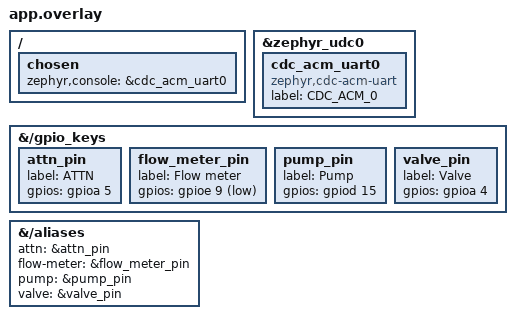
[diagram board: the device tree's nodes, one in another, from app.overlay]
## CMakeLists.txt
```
# Copyright 2023 Blues Inc.  All rights reserved.
# Use of this source code is governed by licenses granted by the
# copyright holder including that found in the LICENSE file.

# SPDX-License-Identifier: MIT

# Set CMake policy behavior
cmake_minimum_required(VERSION 3.20.0)

# Load Zephyr Package
find_package(Zephyr REQUIRED HINTS $ENV{ZEPHYR_BASE})

# Basic Project Configuration
project(nf9
    VERSION 1.0.0
    LANGUAGES C ASM
)
set(CMAKE_C_STANDARD 11)
set(CMAKE_C_STANDARD_REQUIRED ON)
set(CMAKE_C_EXTENSIONS ON)  # required for inline asm

# Create variables to alias path names
set(NOTE_C ${CMAKE_CURRENT_LIST_DIR}/note-c)
set(SRC ${CMAKE_CURRENT_LIST_DIR}/src)

# Set global compile settings
zephyr_get_compile_options_for_lang_as_string(C zephyr_options)
message(STATUS ${zephyr_options})
message(STATUS) # Insert blank line for readability
zephyr_compile_options(
    -ggdb
    -Og
    -Wall
    # -Wextra
    -Wno-unused-parameter
    # -Wpedantic
)
zephyr_get_compile_options_for_lang_as_string(C zephyr_options)
message(STATUS ${zephyr_options})
message(STATUS) # Insert blank line for readability

# Let Zephyr build additional 3rd party libs (e.g. `note-c`) with `app`
target_sources(app
    PRIVATE ${NOTE_C}/n_atof.c
    PRIVATE ${NOTE_C}/n_b64.c
    PRIVATE ${NOTE_C}/n_cjson.c
    PRIVATE ${NOTE_C}/n_cjson_helpers.c
    PRIVATE ${NOTE_C}/n_const.c
    PRIVATE ${NOTE_C}/n_ftoa.c
    PRIVATE ${NOTE_C}/n_helpers.c
    PRIVATE ${NOTE_C}/n_hooks.c
    PRIVATE ${NOTE_C}/n_i2c.c
    PRIVATE ${NOTE_C}/n_md5.c
    PRIVATE ${NOTE_C}/n_printf.c
    PRIVATE ${NOTE_C}/n_request.c
    PRIVATE ${NOTE_C}/n_serial.c
    PRIVATE ${NOTE_C}/n_str.c
    PRIVATE ${NOTE_C}/n_ua.c
    PRIVATE ${SRC}/main.c
    PRIVATE ${SRC}/notecard.c
)

target_include_directories(app
    PRIVATE ${NOTE_C}
)

target_compile_definitions(app
    PRIVATE -DUSE_VALVE=1
)

# WARNING: These options are overriden by `zephyr_compile_options()`
target_compile_options(app
    PRIVATE -ggdb
    PRIVATE -Og
    PRIVATE -Wall
    PRIVATE -Wextra
    # PRIVATE -Wpedantic
    PRIVATE -Wimplicit-fallthrough=2
    PRIVATE -Wunused-parameter
)
```

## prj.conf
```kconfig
CONFIG_GPIO=y
CONFIG_USB_DEVICE_STACK=y
CONFIG_USB_DEVICE_PRODUCT="Notecard Valve Monitor"
CONFIG_USB_DEVICE_VID=4440

CONFIG_SERIAL=y
CONFIG_CONSOLE=y
CONFIG_UART_CONSOLE=y
CONFIG_UART_LINE_CTRL=y

CONFIG_I2C=y

CONFIG_NEWLIB_LIBC=y

# Debugging Configuration
# CONFIG_OPENOCD_SUPPORT=y
CONFIG_PRINTK=y
```

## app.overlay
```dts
/*
 * Copyright (c) 2021 Nordic Semiconductor ASA
 *
 * SPDX-License-Identifier: Apache-2.0
 */

/ {
	chosen {
		zephyr,console = &cdc_acm_uart0;
	};
};

&zephyr_udc0 {
	cdc_acm_uart0: cdc_acm_uart0 {
		compatible = "zephyr,cdc-acm-uart";
		label = "CDC_ACM_0";
	};
};

&{/gpio_keys} {
	attn_pin: attn_pin {
		label = "ATTN";
		gpios = <&gpioa 5 GPIO_ACTIVE_HIGH>;
	};

	flow_meter_pin: flow_meter_pin {
		label = "Flow meter";
		gpios = <&gpioe 9 GPIO_ACTIVE_LOW>;
	};

	pump_pin: pump_pin {
		label = "Pump";
		gpios = <&gpiod 15 GPIO_ACTIVE_HIGH>;
	};

	valve_pin: valve_pin {
		label = "Valve";
		gpios = <&gpioa 4 GPIO_ACTIVE_HIGH>;
	};
};

&{/aliases} {
	attn = &attn_pin;
	flow-meter = &flow_meter_pin;
	pump = &pump_pin;
	valve = &valve_pin;
};
```

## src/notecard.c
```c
#include "notecard.h"

#include <zephyr/drivers/i2c.h>
#include <zephyr/drivers/uart.h>
#include <zephyr/kernel.h>

static const size_t REQUEST_HEADER_SIZE = 2;

const struct device *i2c_dev = NULL;
bool i2c1_initialized = false;

uint32_t platform_millis(void)
{
    return k_uptime_get_32();
}

void platform_delay(uint32_t ms)
{
    k_msleep(ms);
}

const char *noteI2cReceive(uint16_t device_address_, uint8_t *buffer_, uint16_t size_, uint32_t *available_)
{
    // Let the Notecard know that we are getting ready to read some data
    uint8_t size_buf[2];
    size_buf[0] = 0;
    size_buf[1] = (uint8_t)size_;
    uint8_t write_result = i2c_write(i2c_dev, size_buf, sizeof(size_buf), device_address_);

    if (write_result != 0)
    {
        return "i2c: Unable to initate read from the Notecard\n";
    }

    // Read from the Notecard and copy the response bytes into the response buffer
    const int request_length = size_ + REQUEST_HEADER_SIZE;
    uint8_t read_buf[256];
    uint8_t read_result = i2c_read(i2c_dev, read_buf, request_length, device_address_);

    if (read_result != 0)
    {
        return "i2c: Unable to receive data from the Notecard.\n";
    }
    else
    {
        *available_ = (uint32_t)read_buf[0];
        uint8_t bytes_to_read = read_buf[1];
        for (size_t i = 0; i < bytes_to_read; i++)
        {
            buffer_[i] = read_buf[i + 2];
        }

        return NULL;
    }
}

bool noteI2cReset(uint16_t device_address_)
{
    (void)device_address_;

    if (i2c1_initialized)
        return true;

    if (!i2c_dev)
    {
        i2c_dev = DEVICE_DT_GET(DT_NODELABEL(i2c1));
    }

    if (!device_is_ready(i2c_dev))
    {
        printk("i2c: Device is not ready.\n");

        return false;
    }

    printk("i2c: Device is ready.\n");

    i2c1_initialized = true;
    return true;
}

const char *noteI2cTransmit(uint16_t device_address_, uint8_t *buffer_, uint16_t size_)
{
    // Create a buffer that contains the number of bytes and the data to write to the Notecard
    uint8_t write_buf[size_ + 1];
    write_buf[0] = (uint8_t)size_;
    for (size_t i = 0; i < size_; i++)
    {
        write_buf[i + 1] = buffer_[i];
    }

    // Write the message
    uint8_t write_result = i2c_write(i2c_dev, write_buf, sizeof(write_buf), device_address_);

    if (write_result != 0)
    {
        return "i2c: Unable to transmit data to the Notecard\n";
    }
    else
    {
        return NULL;
    }
}

size_t noteLogPrint(const char *message_)
{
    if (message_)
    {
        printk("%s", message_);
        return 1;
    }

    return 0;
}

bool noteSerialAvailable(void)
{
    bool result = false;

    return result;
}

char noteSerialReceive(void)
{
    char result = 'z';

    return result;
}

bool noteSerialReset(void)
{
    bool result = false;

    return result;
}

void noteSerialTransmit(uint8_t *text_, size_t len_, bool flush_)
{
}
```

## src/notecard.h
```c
#ifndef NOTECARD_H
#define NOTECARD_H

#include <stdbool.h>
#include <stdint.h>
#include <stdlib.h>

void platform_delay(uint32_t ms);
uint32_t platform_millis(void);

const char *noteI2cReceive(uint16_t device_address_, uint8_t *buffer_, uint16_t size_, uint32_t *available_);
bool noteI2cReset(uint16_t device_address_);
const char *noteI2cTransmit(uint16_t device_address_, uint8_t *buffer_, uint16_t size_);

size_t noteLogPrint(const char *message_);

bool noteSerialAvailable(void);
char noteSerialReceive(void);
bool noteSerialReset(void);
void noteSerialTransmit(uint8_t *text_, size_t len_, bool flush_);

#endif // NOTECARD_H
```
